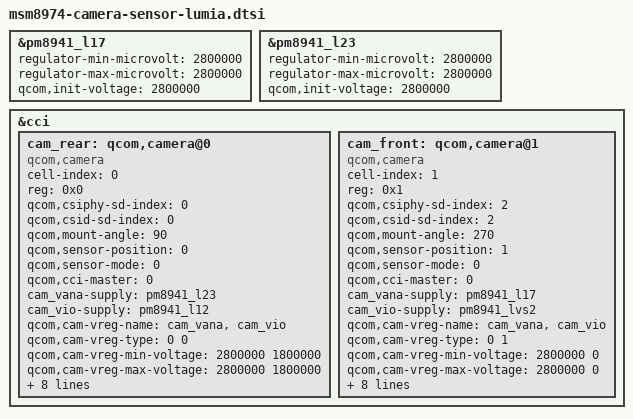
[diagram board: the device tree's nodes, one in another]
/*
 * Camera sensors of the MSM8974 Lumias (Nokia Lumia 930 "martini" and 1520
 * "bandit", same camera hardware), for msm_sensor_driver: the sensor
 * libraries of the camera daemon give the power sequence, the device tree
 * gives the board resources.
 *
 * Rear "Karma" module (SMIA++, module 0x4541, Toshiba die 0x2170, OIS/AF
 * controller at CCI 0x3e): CCI master 0 at 0x10, CSIPHY0/CSID0, 4 lanes,
 * MCLK0 on GPIO 15. Windows (PEP \_SB.CAMS D0 and \_SB.CAMP F0) powers it
 * with L23 2.8 V, L12 1.8 V and GPIO 83 high; no reset GPIO is driven.
 *
 * Front "Skype_HD" module (SMIA, module 0x6A30): CCI master 0 at 0x10,
 * CSIPHY2/CSID2, 1 lane, MCLK2 on GPIO 17. Windows (PEP \_SB.CAMF D0)
 * powers it with L17 2.8 V, GPIO 18 high, then LVS2.
 *
 * GPIO 89-92 are left alone, as on Windows: undriven they read high, so
 * driving them low could hold a module in reset. The rear module also needs
 * TLMM_SPARE_REG cleared (board-8974-gpiomux.c).
 *
 * Copyright (c) 2026, Lorenzo Giannoccaro. GPLv2 only.
 */

/* Both modules want 2.8 V analog; nothing else on these boards uses L17/L23. */
&pm8941_l17 {
	regulator-min-microvolt = <2800000>;
	regulator-max-microvolt = <2800000>;
	qcom,init-voltage = <2800000>;
};

&pm8941_l23 {
	regulator-min-microvolt = <2800000>;
	regulator-max-microvolt = <2800000>;
	qcom,init-voltage = <2800000>;
};

&cci {
	cam_rear: qcom,camera@0 {
		cell-index = <0>;
		compatible = "qcom,camera";
		reg = <0x0>;
		qcom,csiphy-sd-index = <0>;
		qcom,csid-sd-index = <0>;
		qcom,mount-angle = <90>;
		qcom,sensor-position = <0>;
		qcom,sensor-mode = <0>;
		qcom,cci-master = <0>;
		cam_vana-supply = <&pm8941_l23>;
		cam_vio-supply = <&pm8941_l12>;
		qcom,cam-vreg-name = "cam_vana", "cam_vio";
		qcom,cam-vreg-type = <0 0>;
		qcom,cam-vreg-min-voltage = <2800000 1800000>;
		qcom,cam-vreg-max-voltage = <2800000 1800000>;
		qcom,cam-vreg-op-mode = <80000 0>;
		qcom,gpio-no-mux = <0>;
		gpios = <&msmgpio 15 0>,	/* CAM_MCLK0 */
			<&msmgpio 83 0>;	/* camera platform enable */
		qcom,gpio-vdig = <1>;
		qcom,gpio-req-tbl-num = <0 1>;
		qcom,gpio-req-tbl-flags = <1 0>;
		qcom,gpio-req-tbl-label = "CAMIF_MCLK0", "CAM_PLATFORM_EN";
		status = "ok";
	};

	cam_front: qcom,camera@1 {
		cell-index = <1>;
		compatible = "qcom,camera";
		reg = <0x1>;
		qcom,csiphy-sd-index = <2>;
		qcom,csid-sd-index = <2>;
		qcom,mount-angle = <270>;
		qcom,sensor-position = <1>;
		qcom,sensor-mode = <0>;
		qcom,cci-master = <0>;
		cam_vana-supply = <&pm8941_l17>;
		cam_vio-supply = <&pm8941_lvs2>;
		qcom,cam-vreg-name = "cam_vana", "cam_vio";
		qcom,cam-vreg-type = <0 1>;	/* LVS2 is a switch */
		qcom,cam-vreg-min-voltage = <2800000 0>;
		qcom,cam-vreg-max-voltage = <2800000 0>;
		qcom,cam-vreg-op-mode = <80000 0>;
		qcom,gpio-no-mux = <0>;
		gpios = <&msmgpio 17 0>,	/* CAM_MCLK2 */
			<&msmgpio 18 0>;	/* front module enable (XSHUTDOWN) */
		qcom,gpio-vdig = <1>;
		qcom,gpio-req-tbl-num = <0 1>;
		qcom,gpio-req-tbl-flags = <1 0>;
		qcom,gpio-req-tbl-label = "CAMIF_MCLK2", "CAM_FRONT_EN";
		status = "ok";
	};
};
